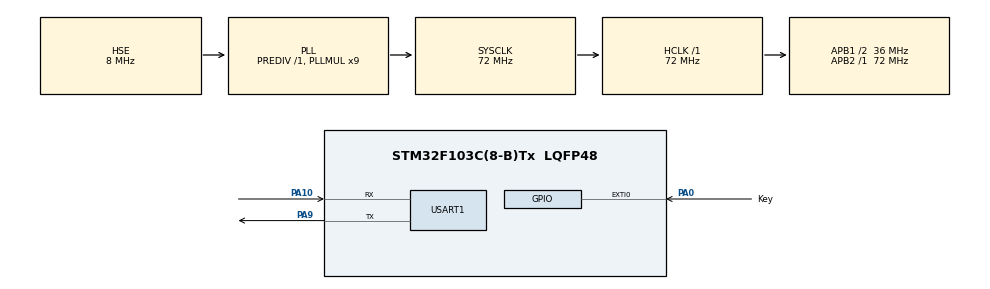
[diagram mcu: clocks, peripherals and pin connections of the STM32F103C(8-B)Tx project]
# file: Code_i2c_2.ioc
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Mcu.Family=STM32F1
Mcu.Name=STM32F103C(8-B)Tx
Mcu.Package=LQFP48
NVIC.EXTI0_IRQn=true\:0\:0\:false\:true\:true\:1\:true\:true
NVIC.PriorityGroup=NVIC_PRIORITYGROUP_4
NVIC.USART1_IRQn=true\:0\:0\:false\:true\:true\:2\:true\:true
PA0-WKUP.GPIO_Label=Key
PA0-WKUP.Signal=GPXTI0
PA10.Mode=Asynchronous
PA10.Signal=USART1_RX
PA13.Signal=SYS_JTMS-SWDIO
PA14.Signal=SYS_JTCK-SWCLK
PA9.Mode=Asynchronous
PA9.Signal=USART1_TX
PB6.Signal=I2C1_SCL
PD0-OSC_IN.Mode=HSE-External-Oscillator
PD0-OSC_IN.Signal=RCC_OSC_IN
PD1-OSC_OUT.Mode=HSE-External-Oscillator
PD1-OSC_OUT.Signal=RCC_OSC_OUT
ProjectManager.HeapSize=0x200
ProjectManager.StackSize=0x400
ProjectManager.TargetToolchain=MDK-ARM V5.32
RCC.AHBFreq_Value=72000000
RCC.APB1CLKDivider=RCC_HCLK_DIV2
RCC.APB1Freq_Value=36000000
RCC.APB1TimFreq_Value=72000000
RCC.APB2Freq_Value=72000000
RCC.APB2TimFreq_Value=72000000
RCC.HCLKFreq_Value=72000000
RCC.PLLMUL=RCC_PLL_MUL9
RCC.PLLSourceVirtual=RCC_PLLSOURCE_HSE
RCC.SYSCLKFreq_VALUE=72000000
RCC.SYSCLKSource=RCC_SYSCLKSOURCE_PLLCLK
RCC.USBFreq_Value=72000000
USART1.VirtualMode=VM_ASYNC
VP_SYS_VS_ND.Mode=No_Debug
board=custom

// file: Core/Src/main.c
/* USER CODE BEGIN Header */
/**
  ******************************************************************************
  * @file           : main.c
  * @brief          : Main program body
  ******************************************************************************
  * @attention
  *
  * Copyright (c) 2022 STMicroelectronics.
  * All rights reserved.
  *
  * This software is licensed under terms that can be found in the LICENSE file
  * in the root directory of this software component.
  * If no LICENSE file comes with this software, it is provided AS-IS.
  *
  ******************************************************************************
  */
/* USER CODE END Header */
#include "main.h"
#include "usart.h"
#include "gpio.h"

/* USER CODE BEGIN Includes */
#include<stdio.h>
#include <string.h>
#include "i2c.h"
#include "eeprom.h"
/* USER CODE END Includes */

void SystemClock_Config(void);
static void MX_NVIC_Init(void);

int main(void)
{
  /* USER CODE BEGIN 1 */
    char tx_data[20]={"Hello I2C"};
    char rx_data[20]={0};

  /* USER CODE END 1 */

  /* MCU Configuration--------------------------------------------------------*/

  /* Reset of all peripherals, Initializes the Flash interface and the Systick. */
  HAL_Init();

  /* Configure the system clock */
  SystemClock_Config();

  /* USER CODE BEGIN SysInit */
    I2C_Init();
  /* USER CODE END SysInit */

  /* Initialize all configured peripherals */
  MX_GPIO_Init();
  MX_USART1_UART_Init();

  /* Initialize interrupts */
  MX_NVIC_Init();
  /* USER CODE BEGIN 2 */
  printf("*************\r\n");
  printf("I2C Test 2\r\n");
  printf("*************\r\n");
  /* USER CODE END 2 */

  /* Infinite loop */
  while (1)
  {

    /* USER CODE BEGIN 3 */
      if(get_keyvalue()){
        //发送数据
             EEPROM_WriteNByte(0,(uint8_t *)tx_data,sizeof(tx_data));
             HAL_Delay(1);
             printf("EEPROM Write:%s\r\n",tx_data);

             EEPROM_ReadNByte(0,(uint8_t *)rx_data,sizeof(rx_data));
             HAL_Delay(1);
             printf("EEPROM Read:%s\r\n",rx_data);

          //清空缓存
          memset(rx_data,0,sizeof(rx_data));
      }
  }
  /* USER CODE END 3 */
}

void SystemClock_Config(void)
{
  RCC_OscInitTypeDef RCC_OscInitStruct = {0};
  RCC_ClkInitTypeDef RCC_ClkInitStruct = {0};

  /** Initializes the RCC Oscillators according to the specified parameters
  * in the RCC_OscInitTypeDef structure.
  */
  RCC_OscInitStruct.OscillatorType = RCC_OSCILLATORTYPE_HSE;
  RCC_OscInitStruct.HSEState = RCC_HSE_ON;
  RCC_OscInitStruct.HSEPredivValue = RCC_HSE_PREDIV_DIV1;
  RCC_OscInitStruct.HSIState = RCC_HSI_ON;
  RCC_OscInitStruct.PLL.PLLState = RCC_PLL_ON;
  RCC_OscInitStruct.PLL.PLLSource = RCC_PLLSOURCE_HSE;
  RCC_OscInitStruct.PLL.PLLMUL = RCC_PLL_MUL9;
  if (HAL_RCC_OscConfig(&RCC_OscInitStruct) != HAL_OK)
  {
    Error_Handler();
  }
  /** Initializes the CPU, AHB and APB buses clocks
  */
  RCC_ClkInitStruct.ClockType = RCC_CLOCKTYPE_HCLK|RCC_CLOCKTYPE_SYSCLK
                              |RCC_CLOCKTYPE_PCLK1|RCC_CLOCKTYPE_PCLK2;
  RCC_ClkInitStruct.SYSCLKSource = RCC_SYSCLKSOURCE_PLLCLK;
  RCC_ClkInitStruct.AHBCLKDivider = RCC_SYSCLK_DIV1;
  RCC_ClkInitStruct.APB1CLKDivider = RCC_HCLK_DIV2;
  RCC_ClkInitStruct.APB2CLKDivider = RCC_HCLK_DIV1;

  if (HAL_RCC_ClockConfig(&RCC_ClkInitStruct, FLASH_LATENCY_2) != HAL_OK)
  {
    Error_Handler();
  }
}

/**
  * @brief NVIC Configuration.
  * @retval None
  */
static void MX_NVIC_Init(void)
{
  /* EXTI0_IRQn interrupt configuration */
  HAL_NVIC_SetPriority(EXTI0_IRQn, 0, 0);
  HAL_NVIC_EnableIRQ(EXTI0_IRQn);
  /* USART1_IRQn interrupt configuration */
  HAL_NVIC_SetPriority(USART1_IRQn, 0, 0);
  HAL_NVIC_EnableIRQ(USART1_IRQn);
}

void Error_Handler(void)
{
  __disable_irq();
  while (1)
  {
  }
}
